# M01_DataflowController register map
Vendor: Babel; File version: 1.0
M01_DataflowController Register Map
CPU: CM0 r0p0, little endian, no MPU, no FPU
Registers are 32-bit, read-write, reset 0x0 unless marked. A register's access mark holds for its fields unless they carry their own. Offsets are from the block's base; lines under a group give offsets from that group; [hi:lo] are bit positions; {n}, {i} and the like mark numbered series; 'fields as' and 'values as' point back to an identical list; <NAME> marks a mode.

## Memory map
0x00000000 M01_DataflowController

## M01_DataflowController
Base 0x00000000
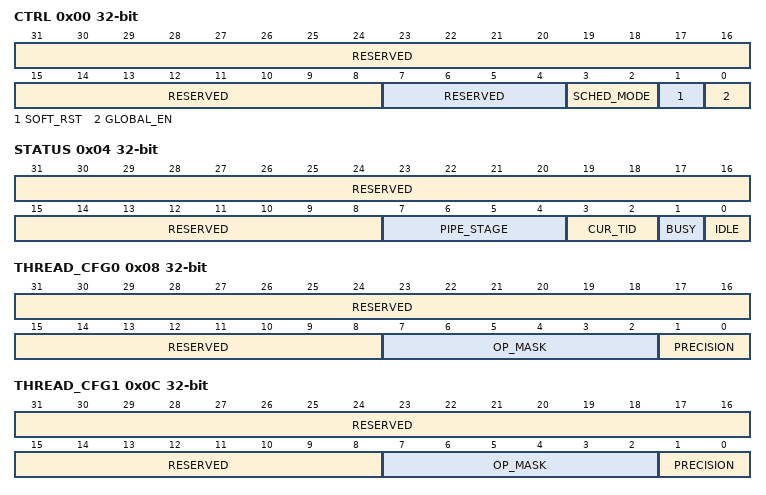
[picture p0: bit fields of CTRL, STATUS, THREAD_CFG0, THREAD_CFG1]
0x00 CTRL — 控制寄存器：全局使能、软复位、调度模式
  [31:8] RESERVED - — 保留，必须写 0
  [7:4] RESERVED - — 保留，必须写 0
  [3:2] SCHED_MODE — 调度模式。00=顺序, 01=轮询, 10=优先级
  [1] SOFT_RST — 软复位。写 1 触发内部复位，自清零
  [0] GLOBAL_EN — 全局使能。1=使能，0=禁用
0x04 STATUS ro — 状态寄存器：IDLE/BUSY、当前 TID、流水线阶段
  [31:8] RESERVED - — 保留
  [7:4] PIPE_STAGE — 当前流水线阶段 (0-F)
  [3:2] CUR_TID — 当前线程 ID (0-1)
  [1] BUSY — 忙标志。1=正在处理
  [0] IDLE — 空闲标志。1=模块空闲
0x08 THREAD_CFG0 — 线程 0 配置：精度、算子掩码
  [31:8] RESERVED - — 保留，必须写 0
  [7:2] OP_MASK — 算子掩码。bit[n]=1 启用算子 n
  [1:0] PRECISION — 精度选择。00=INT8, 01=FP16, 10=BF16
0x0C THREAD_CFG1 — 线程 1 配置：同上
  fields as THREAD_CFG0
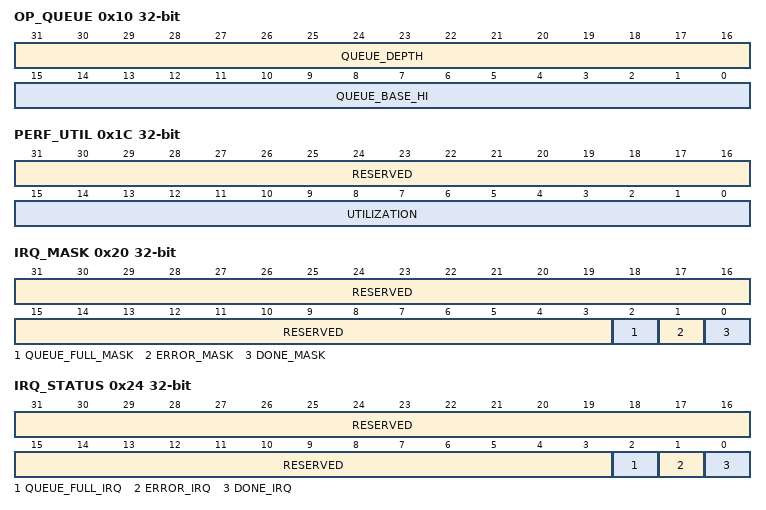
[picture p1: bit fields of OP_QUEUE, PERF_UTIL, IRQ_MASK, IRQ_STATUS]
0x10 OP_QUEUE — 操作队列：基地址高 16 位、深度
  [31:16] QUEUE_DEPTH — 队列深度（条目数）
  [15:0] QUEUE_BASE_HI — 队列基地址高 16 位
0x14 PERF_CNT0 ro — 线程 0 完成算子计数
  [31:0] COUNT
0x18 PERF_CNT1 ro — 线程 1 完成算子计数
  [31:0] COUNT
0x1C PERF_UTIL ro — 流水线利用率（Q16 格式）
  [31:16] RESERVED - — 保留
  [15:0] UTILIZATION — 流水线利用率（Q0.16 定点格式，0x10000=100%）
0x20 IRQ_MASK — 中断使能掩码
  [31:3] RESERVED - — 保留，必须写 0
  [2] QUEUE_FULL_MASK — 队列满中断使能。1=使能
  [1] ERROR_MASK — 错误中断使能。1=使能
  [0] DONE_MASK — 完成中断使能。1=使能
0x24 IRQ_STATUS w1c — 中断状态，写 1 清零
  [31:3] RESERVED - — 保留
  [2] QUEUE_FULL_IRQ — 队列满中断。写 1 清零
  [1] ERROR_IRQ — 错误中断。写 1 清零
  [0] DONE_IRQ — 完成中断。写 1 清零
